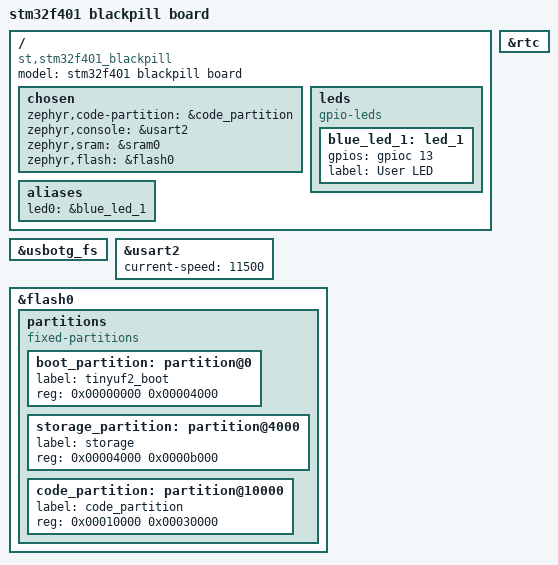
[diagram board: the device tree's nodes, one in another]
/*
 * Copyright (c) 2017 Linaro Limited
 *
 * SPDX-License-Identifier: Apache-2.0
 */

/dts-v1/;
#include <st/f4/stm32f401Xc.dtsi>

/ {
	model = "stm32f401 blackpill board";
	compatible = "st,stm32f401_blackpill", "st,stm32f401";

	chosen {
		zephyr,code-partition = &code_partition;
		zephyr,console = &usart2;
		//zephyr,shell-uart = &usart2;
		zephyr,sram = &sram0;
		zephyr,flash = &flash0;
		//zephyr,ccm = &ccm0;
		//zephyr,can-primary = &can2;
	};

	leds {
		compatible = "gpio-leds";
		blue_led_1: led_1 {
			gpios = <&gpioc 13 GPIO_ACTIVE_HIGH>;
			label = "User LED";
		};
	};

	aliases {
		led0 = &blue_led_1;
	};
};

&rtc {
	status = "okay";
};

&usbotg_fs {
	status = "okay";
};

&usart2 {
	current-speed = <11500>;
	status = "okay";
};

&flash0 {
	partitions {
		compatible = "fixed-partitions";
		#address-cells = <1>;
		#size-cells = <1>;

		boot_partition: partition@0 {
			label = "tinyuf2_boot";
			reg = <0x00000000 0x00004000>;
		};
		
		storage_partition: partition@4000 {
			label = "storage";
			reg = <0x00004000 0x0000b000>;
		};
		
		code_partition: partition@10000 {
			label = "code_partition";
			reg = <0x00010000 0x00030000>;
		};
	};
};
